VERSION ""

NS_ :

BS_:

BU_:

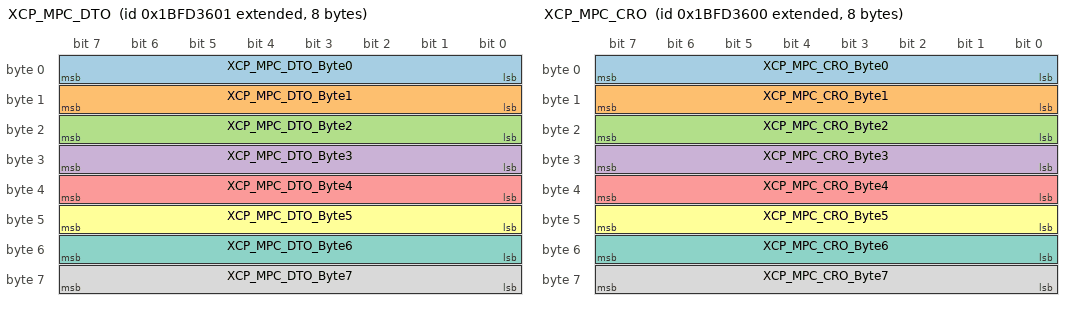
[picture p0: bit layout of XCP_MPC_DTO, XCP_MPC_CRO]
BO_ 2617062913 XCP_MPC_DTO: 8 Vector__XXX
 SG_ XCP_MPC_DTO_Byte0 : 0|8@1- (1,0) [0|255] "" Vector__XXX
 SG_ XCP_MPC_DTO_Byte1 : 8|8@1- (1,0) [0|255] "" Vector__XXX
 SG_ XCP_MPC_DTO_Byte2 : 16|8@1- (1,0) [0|255] "" Vector__XXX
 SG_ XCP_MPC_DTO_Byte3 : 24|8@1- (1,0) [0|255] "" Vector__XXX
 SG_ XCP_MPC_DTO_Byte4 : 32|8@1- (1,0) [0|255] "" Vector__XXX
 SG_ XCP_MPC_DTO_Byte5 : 40|8@1- (1,0) [0|255] "" Vector__XXX
 SG_ XCP_MPC_DTO_Byte6 : 48|8@1- (1,0) [0|255] "" Vector__XXX
 SG_ XCP_MPC_DTO_Byte7 : 56|8@1- (1,0) [0|255] "" Vector__XXX

BO_ 2617062912 XCP_MPC_CRO: 8 Vector__XXX
 SG_ XCP_MPC_CRO_Byte0 : 0|8@1- (1,0) [0|255] "" Vector__XXX
 SG_ XCP_MPC_CRO_Byte1 : 8|8@1- (1,0) [0|255] "" Vector__XXX
 SG_ XCP_MPC_CRO_Byte2 : 16|8@1- (1,0) [0|255] "" Vector__XXX
 SG_ XCP_MPC_CRO_Byte3 : 24|8@1- (1,0) [0|255] "" Vector__XXX
 SG_ XCP_MPC_CRO_Byte4 : 32|8@1- (1,0) [0|255] "" Vector__XXX
 SG_ XCP_MPC_CRO_Byte5 : 40|8@1- (1,0) [0|255] "" Vector__XXX
 SG_ XCP_MPC_CRO_Byte6 : 48|8@1- (1,0) [0|255] "" Vector__XXX
 SG_ XCP_MPC_CRO_Byte7 : 56|8@1- (1,0) [0|255] "" Vector__XXX

BA_DEF_ BO_  "GenMsgSendType" ENUM  "Cyclic","not_used","not_used","not_used","not_used","not_used","not_used","IfActive","NoMsgSendType";
BA_DEF_ BO_  "MsgType" ENUM  "Application","NM","NMH","TP2.0","ISO-TP","BAP","EID","KS";
BA_DEF_ SG_  "GenSigSendType" ENUM  "Cyclic","OnWrite","OnWriteWithRepetition","OnChange","OnChangeWithRepetition","IfActive","IfActiveWithRepetition","NoSigSendType","OnChangeAndIfActive","OnChangeAndIfActiveWithRepetition";
BA_DEF_ SG_  "GenSigFuncType" ENUM  "NoFunction","MsgCounter","CRC-8","XOR","XOR-2","DatedBit","SW-Kl15","CHK","Constant","Protocol","CRC-8-SAE_J1850";
BA_DEF_ SG_  "GenSigSwitchedByIgnition" ENUM  "No","Yes";
BA_DEF_DEF_  "GenMsgSendType" "NoMsgSendType";
BA_DEF_DEF_  "MsgType" "Application";
BA_DEF_DEF_  "GenSigSendType" "NoSigSendType";
BA_DEF_DEF_  "GenSigFuncType" "NoFunction";
BA_DEF_DEF_  "GenSigSwitchedByIgnition" "Yes";
